# R7FA0E107 register map
Vendor: Renesas Electronics Corporation; Series: RA0; File version: 1.20.00
CPU: CM23 r1p0, little endian, no MPU, no FPU, VTOR, 2 interrupt priority bits, 64 interrupts
Registers are 16-bit, read-write, reset 0x0 unless marked. A register's access mark holds for its fields unless they carry their own. Offsets are from the block's base; [hi:lo] are bit positions; {n}, {i} and the like mark numbered series; 'fields as' and 'values as' point back to an identical list.

## TML32 — 32-bit Interval Timer
Base 0x400A3800
{0x0+2i} ITLCMP0{i} (i=0..1) reset 0xFFFF — Interval Timer Compare Registers 0{i}
{0x0+2i} ITLCMP0{i}_L (i=0..1) 8-bit reset 0xFF (alternate view of ITLCMP0{i}) — Interval Timer Compare Registers 0{i}
{0x1+2i} ITLCMP0{i}_H (i=0..1) 8-bit reset 0xFF (alternate view of ITLCMP0{i}) — Interval Timer Compare Registers 0{i}
0x04 ITLCAP00 ro — Interval Timer Capture Register 00
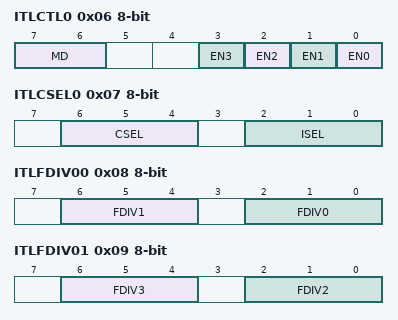
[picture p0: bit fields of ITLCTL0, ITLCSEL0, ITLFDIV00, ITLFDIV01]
0x06 ITLCTL0 8-bit — Interval Timer Control Register
  [7:6] MD — Selection of 8-bit, 16-bit, or 32-bit Counter Mode
    0=The interval timer operates in 8-bit counter mode; 1=The interval timer operates in 16-bit counter mode (channel 0 is connected with channel 1 and channel 2 is connected with channel 3); 2=The interval timer operates in 32-bit counter mode (channels 0 to 3 are connected); 3=Setting prohibited
  [3] EN3 — 8-bit Counter Mode: ITL013 Count Enable
    0=Counting stops; 1=Counting begins
  [2] EN2 — 8-bit Counter Mode: ITL012 Count Enable
    0=Counting stops; 1=Counting begins
  [1] EN1 — 8-bit Counter Mode: ITL001 Count Enable
    0=Counting stops; 1=Counting begins
  [0] EN0 — 8-bit Counter Mode: ITL000 Count Enable
    0=Counting stops; 1=Counting begins
0x07 ITLCSEL0 8-bit — Interval Timer Clock Select Register 0
  [6:4] CSEL — Selection of Interval Timer Count Clock for Capturing (fITL1)
    0=Counting stops; 1=HOCO; 2=MOCO; 3=MOSC; 4=FSXP; 5=Event input from the ELC; other=Others (Setting prohibited)
  [2:0] ISEL — Selection of Interval Timer Count Clock (fITL0)
    values as CSEL
0x08 ITLFDIV00 8-bit — Interval Timer Frequency Division Register 0
  [6:4] FDIV1 — 8-bit Counter Mode: Counter Clock for ITL001
    0=fITL0; 1=fITL0/2; 2=fITL0/4; 3=fITL0/8; 4=fITL0/16; 5=fITL0/32; 6=fITL0/64; 7=fITL0/128
  [2:0] FDIV0 — 8-bit Counter Mode: Counter Clock for ITL000
    values as FDIV1
0x09 ITLFDIV01 8-bit — Interval Timer Frequency Division Register 1
  [6:4] FDIV3 — 8-bit Counter Mode: Counter Clock for ITL013
    values as ITLFDIV00.FDIV1
  [2:0] FDIV2 — 8-bit Counter Mode: Counter Clock for ITL012
    values as ITLFDIV00.FDIV1
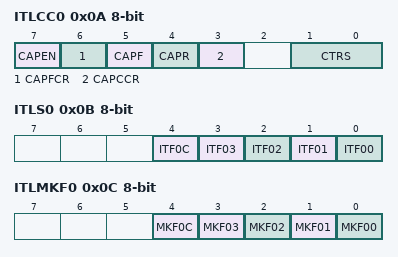
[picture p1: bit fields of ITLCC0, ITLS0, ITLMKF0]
0x0A ITLCC0 8-bit — Interval Timer Capture Control Register 0
  [7] CAPEN — Capture Enable
    0=Capturing is disabled; 1=Capturing is enabled
  [6] CAPFCR — Capture Completion Flag Clear
    0=The value of the capture completion flag CAPF is held; 1=The value of the capture completion flag CAPF is cleared
  [5] CAPF ro — Capture Completion Flag
    0=Capturing has not been completed; 1=Capturing has been completed
  [4] CAPR — Software Capture Trigger
    0=Trigger operation does not proceed; 1=A software trigger for capturing is generated
  [3] CAPCCR — Selection of Capture Counter Clearing After Capturing
    0=The capture counter value is held after the completion of capturing; 1=The capture counter value is cleared after the completion of capturing
  [1:0] CTRS — Selection of Capture Trigger
    0=Software trigger; 1=Interrupt on compare match with ITLCMP01; 2=FSXP (rising edge); 3=Event input from ELC (rising edge)
0x0B ITLS0 8-bit — Interval Timer Status Register
  [4] ITF0C — Capture Detection Flag
    0=Completion of capturing has not been detected; 1=Completion of capturing has been detected
  [n] ITF{n:02} (n=0..3) — Compare Match Detection Flag for Channel {n}
    0=A compare match signal has not been detected in channel {n}; 1=A compare match signal has been detected in channel {n}
0x0C ITLMKF0 8-bit — Interval Timer Match Detection Mask Register
  [4] MKF0C — Mask for Capture Detection Status Flag
    0=ITLS0.ITF0C is not masked; 1=ITLS0.ITF0C is masked
  [n] MKF{n:02} (n=0..3) — Mask for Compare Match Status Flag for Channel {n}
    0=ITLS0.ITF{n:02} is not masked; 1=ITLS0.ITF{n:02} is masked
